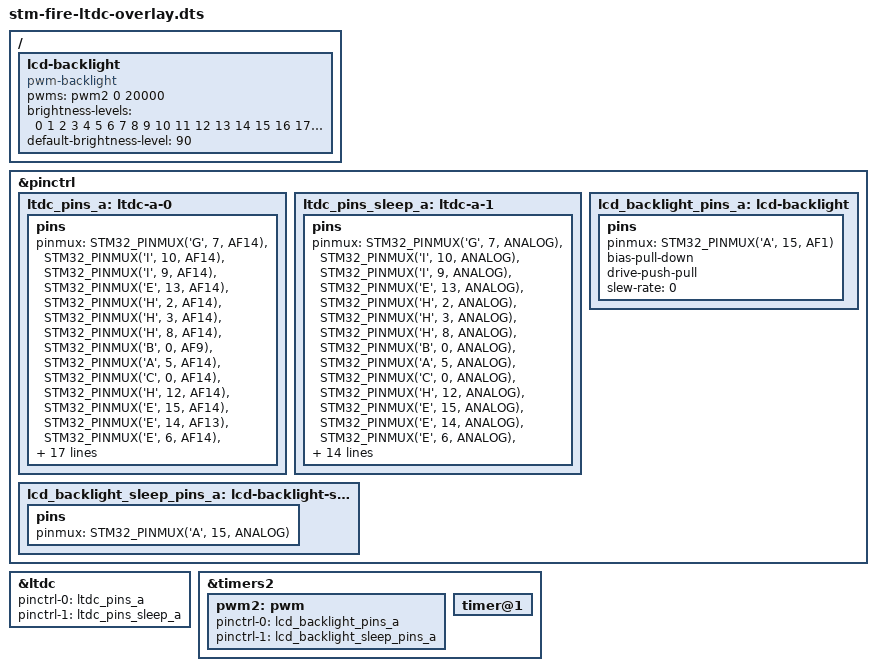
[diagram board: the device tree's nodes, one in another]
// SPDX-License-Identifier: (GPL-2.0+ OR BSD-3-Clause)
/*
 * Copyright (C) STMicroelectronics 2018 - All Rights Reserved
 * Author: Alexandre Torgue <alexandre.torgue@st.com>.
 */

/dts-v1/;
/plugin/;
//#include "../stm32mp157c.dtsi"
#include <dt-bindings/pinctrl/stm32-pinfunc.h>
#include <dt-bindings/input/input.h>
#include <dt-bindings/mfd/st,stpmic1.h>
#include <dt-bindings/gpio/gpio.h>


/ {
    fragment@0{
        target=<&pinctrl>;
        __overlay__ {
			ltdc_pins_a: ltdc-a-0 {
				pins {
					pinmux = <STM32_PINMUX('G',  7, AF14)>, /* LCD_CLK */
						 <STM32_PINMUX('I', 10, AF14)>, /* LCD_HSYNC */
						 <STM32_PINMUX('I',  9, AF14)>, /* LCD_VSYNC */
						 <STM32_PINMUX('E', 13, AF14)>, /* LCD_DE */
						 <STM32_PINMUX('H',  2, AF14)>, /* LCD_R0 */
						 <STM32_PINMUX('H',  3, AF14)>, /* LCD_R1 */
						 <STM32_PINMUX('H',  8, AF14)>, /* LCD_R2 */
						 <STM32_PINMUX('B',  0, AF9)>, /* LCD_R3 */
						 <STM32_PINMUX('A', 5, AF14)>, /* LCD_R4 */
						 <STM32_PINMUX('C',  0, AF14)>, /* LCD_R5 */
						 <STM32_PINMUX('H', 12, AF14)>, /* LCD_R6 */
						 <STM32_PINMUX('E', 15, AF14)>, /* LCD_R7 */
						 <STM32_PINMUX('E', 14, AF13)>, /* LCD_G0 */
						 <STM32_PINMUX('E',  6, AF14)>, /* LCD_G1 */
						 <STM32_PINMUX('H', 13, AF14)>, /* LCD_G2 */
						 <STM32_PINMUX('H', 14, AF14)>, /* LCD_G3 */
						 <STM32_PINMUX('H', 15, AF14)>, /* LCD_G4 */
						 <STM32_PINMUX('I',  0, AF14)>, /* LCD_G5 */
						 <STM32_PINMUX('I',  1, AF14)>, /* LCD_G6 */
						 <STM32_PINMUX('I',  2, AF14)>, /* LCD_G7 */
						 <STM32_PINMUX('D',  9, AF14)>, /* LCD_B0 */
						 <STM32_PINMUX('G', 12, AF14)>, /* LCD_B1 */
						 <STM32_PINMUX('G', 10, AF14)>, /* LCD_B2 */
						 <STM32_PINMUX('D', 10, AF14)>, /* LCD_B3 */
						 <STM32_PINMUX('I',  4, AF14)>, /* LCD_B4 */
						 <STM32_PINMUX('A',  3, AF14)>, /* LCD_B5 */
						 <STM32_PINMUX('B',  8, AF14)>, /* LCD_B6 */
						 <STM32_PINMUX('D',  8, AF14)>; /* LCD_B7 */
					bias-disable;
					drive-push-pull;
					slew-rate = <1>;
				};
			};

			ltdc_pins_sleep_a: ltdc-a-1 {
				pins {
					pinmux = <STM32_PINMUX('G',  7, ANALOG)>, /* LCD_CLK */
						 <STM32_PINMUX('I', 10, ANALOG)>, /* LCD_HSYNC */
						 <STM32_PINMUX('I',  9, ANALOG)>, /* LCD_VSYNC */
						 <STM32_PINMUX('E', 13, ANALOG)>, /* LCD_DE */
						 <STM32_PINMUX('H',  2, ANALOG)>, /* LCD_R0 */
						 <STM32_PINMUX('H',  3, ANALOG)>, /* LCD_R1 */
						 <STM32_PINMUX('H',  8, ANALOG)>, /* LCD_R2 */
						 <STM32_PINMUX('B',  0, ANALOG)>, /* LCD_R3 */
						 <STM32_PINMUX('A',  5, ANALOG)>, /* LCD_R4 */
						 <STM32_PINMUX('C',  0, ANALOG)>, /* LCD_R5 */
						 <STM32_PINMUX('H', 12, ANALOG)>, /* LCD_R6 */
						 <STM32_PINMUX('E', 15, ANALOG)>, /* LCD_R7 */
						 <STM32_PINMUX('E', 14, ANALOG)>, /* LCD_G0 */
						 <STM32_PINMUX('E',  6, ANALOG)>, /* LCD_G1 */
						 <STM32_PINMUX('H', 13, ANALOG)>, /* LCD_G2 */
						 <STM32_PINMUX('H', 14, ANALOG)>, /* LCD_G3 */
						 <STM32_PINMUX('H', 15, ANALOG)>, /* LCD_G4 */
						 <STM32_PINMUX('I',  0, ANALOG)>, /* LCD_G5 */
						 <STM32_PINMUX('I',  1, ANALOG)>, /* LCD_G6 */
						 <STM32_PINMUX('I',  2, ANALOG)>, /* LCD_G7 */
						 <STM32_PINMUX('D',  9, ANALOG)>, /* LCD_B0 */
						 <STM32_PINMUX('G', 12, ANALOG)>, /* LCD_B1 */
						 <STM32_PINMUX('G', 10, ANALOG)>, /* LCD_B2 */
						 <STM32_PINMUX('D', 10, ANALOG)>, /* LCD_B3 */
						 <STM32_PINMUX('I',  4, ANALOG)>, /* LCD_B4 */
						 <STM32_PINMUX('A',  3, ANALOG)>, /* LCD_B5 */
						 <STM32_PINMUX('B',  8, ANALOG)>, /* LCD_B6 */
						 <STM32_PINMUX('D',  8, ANALOG)>; /* LCD_B7 */
				};
			};	
        };
    };

	fragment@1 {
		target=<&ltdc>;
		__overlay__{
			pinctrl-names = "default", "sleep";
			pinctrl-0 = <&ltdc_pins_a>;
			pinctrl-1 = <&ltdc_pins_sleep_a>;
			/*backlight = <&lcd_backlight>;*/
			status = "okay";
		};
	};

	fragment@2 {
		target-path="/";
		__overlay__{
			lcd-backlight {
				compatible = "pwm-backlight"; 
				pwms = <&pwm2 0 20000>;
				brightness-levels = <0 1 2 3 4 5 6 7 8 9 10 11 12 13 14 15 16 17 18 19 20 21 22 23 24 25 26 27 28 29 30 31 32 33 34 35 36 37 38 39 40 41 42 43 44 45 46 47 48 49 50 51 52 53 54 55 56 57 58 59 60 61 62 63 64 65 66 67 68 69 70 71 72 73 74 75 76 77 78 79 80 81 82 83 84 85 86 87 88 89 90 91 92 93 94 95 96 97 98 99 100>;
				default-brightness-level = <90>;
				status = "okay";
			};
		};
	};

	fragment@3 {
		target=<&timers2>;
		__overlay__{
			/* spare dmas for other usage */
			/delete-property/dmas;
			/delete-property/dma-names;
			status = "okay";
			pwm2: pwm {
				pinctrl-0 = <&lcd_backlight_pins_a>;
				pinctrl-1 = <&lcd_backlight_sleep_pins_a>;
				pinctrl-names = "default", "sleep";
				#pwm-cells = <2>;
				status = "okay";
			};
			timer@1 {
				status = "okay";
			};
		};	
	};

	fragment@4 {
		target=<&pinctrl>;
		__overlay__{
			lcd_backlight_pins_a: lcd-backlight {
				pins {
					pinmux = <STM32_PINMUX('A', 15, AF1)>; /* TIM2_CH1 */
					bias-pull-down;
					drive-push-pull;
					slew-rate = <0>;
				};
			};

			lcd_backlight_sleep_pins_a: lcd-backlight-sleep {
				pins {
					pinmux = <STM32_PINMUX('A', 15, ANALOG)>; /* TIM2_CH1 */
				};
			};

		
		};
	};	
};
